# AE302F80F5582AE_CM55_HE_View register map
Vendor: Alif Semiconductor; Series: E3; File version: 1.0
CPU: CM55 r1p0, selectable endian, MPU, FPU, double-precision FPU, DSP, VTOR, 8 interrupt priority bits, 1 SAU regions
Registers are 32-bit, read-write, reset 0x0 unless marked. A register's access mark holds for its fields unless they carry their own. Offsets are from the block's base; [hi:lo] are bit positions; 'fields as' and 'values as' point back to an identical list.

## CLKCTL_SYS
Base 0x1A010000
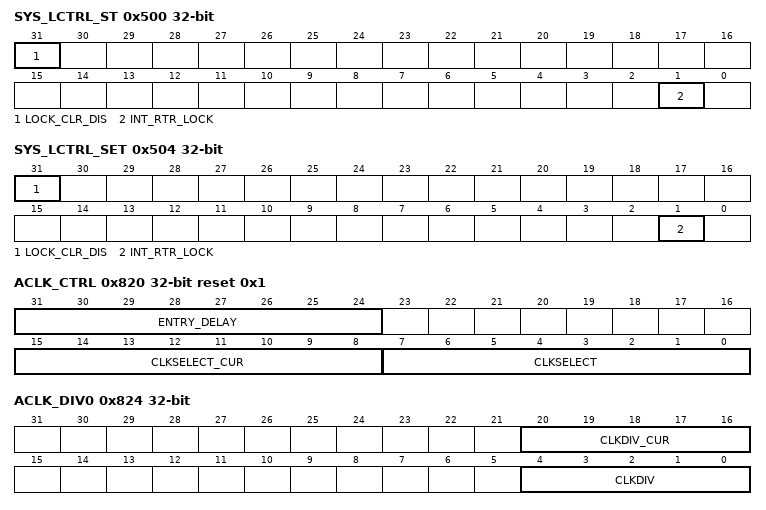
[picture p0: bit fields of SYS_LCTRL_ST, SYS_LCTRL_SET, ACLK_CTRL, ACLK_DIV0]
0x500 SYS_LCTRL_ST ro — System Lock Control Status Register
  [31] LOCK_CLR_DIS — SYS_LCTRL_CLR register behavior indicator
    0=Writes to the SYS_LCTRL_CLR register take effect; 1=Writes to the SYS_LCTRL_CLR register are ignored
  [1] INT_RTR_LOCK — IRQRTR lockdown interface indicator
    0=IRQRTR lockdown interface is de-asserted; 1=IRQRTR lockdown interface is asserted
0x504 SYS_LCTRL_SET — System Lock Control Set Register
  [31] LOCK_CLR_DIS wo — Writing 0x1 to this bit sets the SYS_LCTRL_ST[LOCK_CLR_DIS] bit to 0x1 Writing 0x0 to this bit has no effect on the value of the SYS_LCTRL_ST[LOCK_CLR_DIS] bit This bit always reads as 0x0
  [1] INT_RTR_LOCK wo — Writing 0x1 to this bit sets the SYS_LCTRL_ST[INT_RTR_LOCK] bit to 0x1 Writing 0x0 to this bit has no effect on the value of the SYS_LCTRL_ST[INT_RTR_LOCK] bit This bit always reads as 0x0
0x508 SYS_LCTRL_CLR — System Lock Control Clear Register
  [1] INT_RTR_LOCK wo — Writing 0x1 to this bit sets the SYS_LCTRL_ST[INT_RTR_LOCK] bit to 0x0 Writing 0x0 to this bit has no effect on the value of the SYS_LCTRL_ST[INT_RTR_LOCK] bit This bit always reads as 0x0
0x820 ACLK_CTRL reset 0x1 (reset mask 0xFFFF00FF) — SYST_ACLK Clock Control Register
  [31:24] ENTRY_DELAY — Configure number of idle clock cycles before clock is gated.
  [15:8] CLKSELECT_CUR ro — Currently selected clock source for SYST_ACLK All other values are reserved.
    0=Clock gated; 1=SYST_REFCLK; 2=SYSPLL_CLK divided by ACLK_DIV0[CLKDIV]
  [7:0] CLKSELECT — Select the clock source for SYST_ACLK All other values are reserved. Selecting a reserved value can cause a deadlock.
    values as CLKSELECT_CUR
0x824 ACLK_DIV0 (reset mask 0xFFE0FFFF) — SYST_ACLK Clock Divider 0 Register
  [20:16] CLKDIV_CUR ro — Current value of integer divider applied to SYSPLL_CLK
    0=Divided by 1; 1=Divided by 2; 31=Divided by 32
  [4:0] CLKDIV — Select the value of the integer divider applied to SYSPLL_CLK
    0=Divide by 1; 1=Divide by 2; 31=Divide by 32

## CGU
Base 0x1A602000
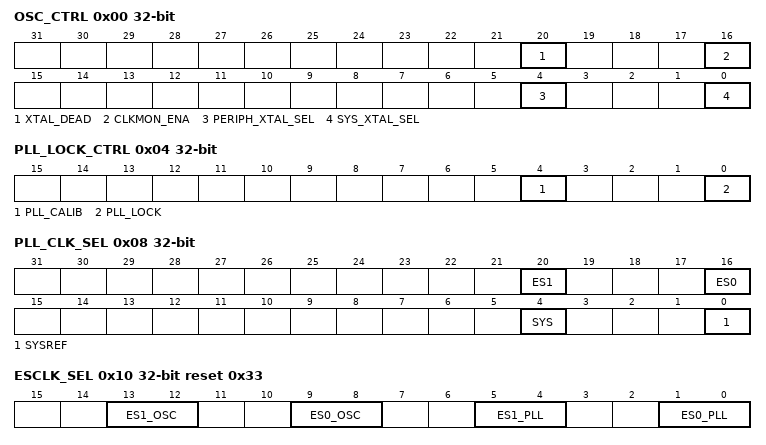
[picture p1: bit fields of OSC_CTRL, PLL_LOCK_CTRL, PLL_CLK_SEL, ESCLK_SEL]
0x00 OSC_CTRL — Oscillator Control Register
  [20] XTAL_DEAD ro — 38.4 MHz crystal-oscillator clock monitor status
    0=No crystal clock dead found; 1=Crystal clock dead detected
  [16] CLKMON_ENA — Enable 38.4 MHz crystal-oscillator clock monitor
    0=Disable clock monitor; 1=Enable clock monitor
  [4] PERIPH_XTAL_SEL — Select oscillator clock source for HFOSC_CLK
    0=Select 38.4 MHz (76.8 MHz / 2) ring-oscillator clock; 1=Select 38.4 MHz crystal-oscillator clock
  [0] SYS_XTAL_SEL — Select oscillator clock source for SYSPLL_CLK, and SYST_REFCLK
    0=Select 76.8 MHz ring-oscillator clock; 1=Select 38.4 MHz crystal-oscillator clock
0x04 PLL_LOCK_CTRL — PLL Lock Control Register
  [4] PLL_CALIB ro — PLL calibration status
    0=PLL not in calibration; 1=PLL in calibration
  [0] PLL_LOCK — PLL lock control
    0=PLL not locked; 1=PLL locked
0x08 PLL_CLK_SEL — PLL Clock Select Register
  [20] ES1 — Select the source for RTSS_HE_CLK
    0=Select a value specified by the ESCLK_SEL[ES1_OSC] field; 1=Select a value specified by the ESCLK_SEL[ES1_PLL] field
  [16] ES0 — Select the source for RTSS_HP_CLK
    0=Select a value specified by the ESCLK_SEL[ES0_OSC] field; 1=Select a value specified by the ESCLK_SEL[ES0_PLL] field
  [4] SYS — Select the source for SYSPLL_CLK
    0=Select oscillator clock source; 1=Select PLL clock source
  [0] SYSREF — Select the source for SYST_REFCLK
    0=Select oscillator clock source; 1=Select PLL clock source
0x10 ESCLK_SEL reset 0x33 — Clock Select Register for M55-HP and M55-HE
  [13:12] ES1_OSC — Select oscillator clock frequency for RTSS_HE_CLK
    0=Select 76.8 MHz ring-oscillator clock; 1=Select 38.4 MHz ring-oscillator clock; 2=Select 76.8 MHz crystal-oscillator clock; 3=Select 38.4 MHz crystal-oscillator clock
  [9:8] ES0_OSC — Select oscillator clock frequency for RTSS_HP_CLK
    values as ES1_OSC
  [5:4] ES1_PLL — Select PLL clock frequency for RTSS_HE_CLK
    0=Select 60 MHz PLL clock; 1=Select 80 MHz PLL clock; 2=Select 120 MHz PLL clock; 3=Select 160 MHz PLL clock
  [1:0] ES0_PLL — Select PLL clock frequency for RTSS_HP_CLK
    0=Select 100 MHz PLL clock; 1=Select 200 MHz PLL clock; 2=Select 300 MHz PLL clock; 3=Select 400 MHz PLL clock
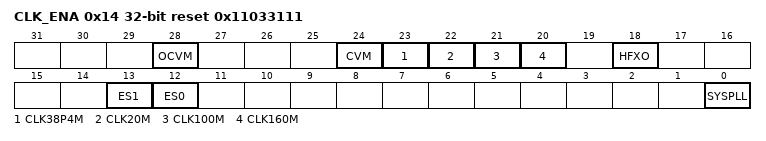
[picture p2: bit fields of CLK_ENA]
0x14 CLK_ENA reset 0x11033111 — Clock Enable Register
  [all] fields
    0=Disable clock; 1=Enable clock
  [28] OCVM — Enable SRAM1 clock
  [24] CVM — Enable SRAM0 clock
  [23] CLK38P4M — Enable HFOSC_CLK
  [22] CLK20M — Enable USB_CLK and 10M_CLK
  [21] CLK100M — Enable 100M_CLK
  [20] CLK160M — Enable 160M_CLK
  [18] HFXO — Enable clock to the HFXO_OUT pin
  [13] ES1 — Enable RTSS_HE_CLK
  [12] ES0 — Enable RTSS_HP_CLK
  [0] SYSPLL — Enable SYSPLL_CLK
0x20 CGU_IRQ ro — CGU Interrupt Status Register
  [0] XTAL_DEAD read-clears — 38.4 MHz crystal-oscillator dead. Active high, read to clear. Note: The XTAL_DEAD interrupt is mapped to the Secure Enclave.
